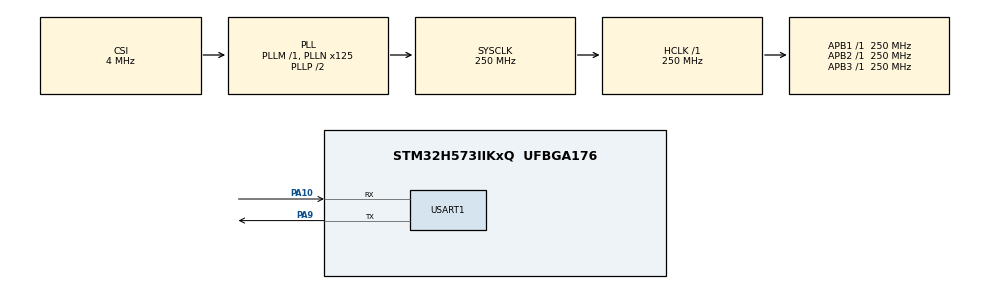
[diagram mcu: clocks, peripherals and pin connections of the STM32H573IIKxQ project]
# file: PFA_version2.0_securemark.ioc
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BOOTPATH.BootPathName=LEGACY
BOOTPATH.UserSelectedBootPath=LEGACY
CORTEX_M33_NS.userName=CORTEX_M33
HASH.Algorithm=HASH_ALGOSELECTION_SHA256
HASH.pKey=__NULL
Mcu.Family=STM32H5
Mcu.Name=STM32H573IIKxQ
Mcu.Package=UFBGA176
NVIC.PriorityGroup=NVIC_PRIORITYGROUP_4
PA10.Mode=Asynchronous
PA10.Signal=USART1_RX
PA9.Mode=Asynchronous
PA9.Signal=USART1_TX
PH0-OSC_IN(PH0).Mode=HSE-DIG-External-Clock-Source
PH0-OSC_IN(PH0).Signal=RCC_OSC_IN
ProjectManager.HeapSize=0x200
ProjectManager.StackSize=0x400
ProjectManager.TargetToolchain=STM32CubeIDE
RCC.ADCFreq_Value=250000000
RCC.AHBFreq_Value=250000000
RCC.APB1Freq_Value=250000000
RCC.APB1TimFreq_Value=250000000
RCC.APB2Freq_Value=250000000
RCC.APB2TimFreq_Value=250000000
RCC.APB3Freq_Value=250000000
RCC.CSI_VALUE=4000000
RCC.CortexFreq_Value=250000000
RCC.EPOD_VALUE=4000000
RCC.HCLKFreq_Value=250000000
RCC.HSE_VALUE=25000000
RCC.HSI48_VALUE=48000000
RCC.HSI_VALUE=64000000
RCC.LSE_VALUE=32768
RCC.LSIRC_VALUE=32000
RCC.PLLFRACN=0
RCC.PLLN=125
RCC.SYSCLKFreq_VALUE=250000000
RCC.SYSCLKSource=RCC_SYSCLKSOURCE_PLLCLK
RCC.USBFreq_Value=48000000
RCC.VCOOutputFreq_Value=500000000
USART1.VirtualMode-Asynchronous=VM_ASYNC
VP_AES_VS_AES.Mode=AES_Activate
VP_BOOTPATH_VS_BOOTPATH.Mode=BP_Activate
VP_CORTEX_M33_NS_VS_Hclk.Mode=Hclk_Mode
VP_HASH_VS_HASH.Mode=HASH_Activate
VP_ICACHE_VS_ICACHE.Mode=DefaultMode
VP_MEMORYMAP_VS_MEMORYMAP.Mode=CurAppReg
VP_PKA_VS_PKA.Mode=PKA_Activate
VP_PWR_VS_LPOM.Mode=PowerOptimisation
VP_PWR_VS_SECSignals.Mode=Security/Privilege
VP_RNG_VS_RNG.Mode=RNG_Activate
board=custom

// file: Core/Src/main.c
/* USER CODE BEGIN Header */
/**
  ******************************************************************************
  * @file           : main.c
  * @brief          : Main program body
  ******************************************************************************
  * @attention
  *
  * Copyright (c) 2025 STMicroelectronics.
  * All rights reserved.
  *
  * This software is licensed under terms that can be found in the LICENSE file
  * in the root directory of this software component.
  * If no LICENSE file comes with this software, it is provided AS-IS.
  *
  ******************************************************************************
  */
/* USER CODE END Header */
#include "main.h"
#include "aes.h"
#include "hash.h"
#include "icache.h"
#include "memorymap.h"
#include "pka.h"
#include "rng.h"
#include "usart.h"
#include "gpio.h"

/* USER CODE BEGIN Includes */
#include "mbedtls_config.h"
//#include "ee_aes.h"
#include "th_lib.h"
#include <stdio.h>
#include <string.h>
#include <stdlib.h>
#include "aes_alt.h"
#include "mbedtls/aes.h"
#include "mbedtls/sha256.h"
#include "sha256_alt.h"

#include "hash.h"
/*
#include "mbedtls/platform_util.h"
#include "mbedtls/platform.h"
#include "hash_stm32.h"
*/
/* USER CODE END Includes */

/* USER CODE BEGIN PV */

mbedtls_aes_context aes_ctx;
mbedtls_sha256_context sha_ctx ;

uint8_t key[16] = {
    0x01, 0x02, 0x03, 0x04,
    0x05, 0x06, 0x07, 0x08,
    0x09, 0x0A, 0x0B, 0x0C,
    0x0D, 0x0E, 0x0F, 0x10
};

uint8_t iv[16] = {
    0x11, 0x12, 0x13, 0x14,
    0x15, 0x16, 0x17, 0x18,
    0x19, 0x1A, 0x1B, 0x1C,
    0x1D, 0x1E, 0x1F, 0x20
};

uint8_t message_buffer[32];
uint8_t message_list[64]="hello from STM32 SecureMark";

/* USER CODE END PV */

void SystemClock_Config(void);
/* USER CODE BEGIN PFP */
#define PUTCHAR_PROTOTYPE int __io_putchar(int ch)
/* USER CODE END PFP */

/* USER CODE BEGIN 0 */
/*int _write(int file, char *ptr, int len){

	HAL_UART_Transmit(&huart1, (uint8_t *)ptr, len, 1000);
	  return len;
}*/
/* USER CODE END 0 */

int main(void)
{

  /* USER CODE BEGIN 1 */
//	 uint32_t aes_time_sw=0;
	 uint32_t aes_time_hw=0;
	 uint32_t sha_time_hw=0;
	  uint32_t t0=0;
	  uint32_t t1=0;

  /* USER CODE END 1 */

  /* MCU Configuration--------------------------------------------------------*/

  /* Reset of all peripherals, Initializes the Flash interface and the Systick. */
  HAL_Init();

  /* Configure the system clock */
  SystemClock_Config();

  /* USER CODE BEGIN SysInit */
  th_timestamp_initialize();
  /* USER CODE END SysInit */

  /* Initialize all configured peripherals */
  MX_GPIO_Init();
  MX_ICACHE_Init();
  MX_AES_Init();
  MX_HASH_Init();
  MX_RNG_Init();
  MX_PKA_Init();
  MX_USART1_UART_Init();
  /* USER CODE BEGIN 2 */
 //AES TEST
  t0= th_timestamp();

  mbedtls_aes_init(&aes_ctx);
  mbedtls_aes_setkey_enc(&aes_ctx, key, 128);
  mbedtls_aes_crypt_ecb(&aes_ctx, MBEDTLS_AES_ENCRYPT,message_buffer, message_list);

  t1= th_timestamp();
   aes_time_hw=t1-t0 ;

    printf("AES encryption Hw took %lu microseconds\r\n", aes_time_hw);

    mbedtls_aes_free(&aes_ctx);

    //SHA_256 TEST
    t0= th_timestamp();

    mbedtls_sha256_init(&sha_ctx);
  uint32_t rets=  mbedtls_sha256_starts_ret(&sha_ctx, 0);
  uint32_t retu=  mbedtls_sha256_update_ret(&sha_ctx,  message_list, strlen((char *)message_list));
  uint32_t retf=  mbedtls_sha256_finish_ret(&sha_ctx, message_buffer);

    t1= th_timestamp();
    sha_time_hw=t1-t0 ;

    printf("SHA_256 Hash Hw took %lu microseconds\r\n", sha_time_hw);
    mbedtls_sha256_free(&sha_ctx);
  /* USER CODE END 2 */

  /* Infinite loop */
   while (1)
  {

  }
}

void SystemClock_Config(void)
{
  RCC_OscInitTypeDef RCC_OscInitStruct = {0};
  RCC_ClkInitTypeDef RCC_ClkInitStruct = {0};

  /** Configure the main internal regulator output voltage
  */
  __HAL_PWR_VOLTAGESCALING_CONFIG(PWR_REGULATOR_VOLTAGE_SCALE0);

  while(!__HAL_PWR_GET_FLAG(PWR_FLAG_VOSRDY)) {}

  /** Initializes the RCC Oscillators according to the specified parameters
  * in the RCC_OscInitTypeDef structure.
  */
  RCC_OscInitStruct.OscillatorType = RCC_OSCILLATORTYPE_HSI48|RCC_OSCILLATORTYPE_CSI;
  RCC_OscInitStruct.HSI48State = RCC_HSI48_ON;
  RCC_OscInitStruct.CSIState = RCC_CSI_ON;
  RCC_OscInitStruct.CSICalibrationValue = RCC_CSICALIBRATION_DEFAULT;
  RCC_OscInitStruct.PLL.PLLState = RCC_PLL_ON;
  RCC_OscInitStruct.PLL.PLLSource = RCC_PLL1_SOURCE_CSI;
  RCC_OscInitStruct.PLL.PLLM = 1;
  RCC_OscInitStruct.PLL.PLLN = 125;
  RCC_OscInitStruct.PLL.PLLP = 2;
  RCC_OscInitStruct.PLL.PLLQ = 2;
  RCC_OscInitStruct.PLL.PLLR = 2;
  RCC_OscInitStruct.PLL.PLLRGE = RCC_PLL1_VCIRANGE_2;
  RCC_OscInitStruct.PLL.PLLVCOSEL = RCC_PLL1_VCORANGE_WIDE;
  RCC_OscInitStruct.PLL.PLLFRACN = 0;
  if (HAL_RCC_OscConfig(&RCC_OscInitStruct) != HAL_OK)
  {
    Error_Handler();
  }

  /** Initializes the CPU, AHB and APB buses clocks
  */
  RCC_ClkInitStruct.ClockType = RCC_CLOCKTYPE_HCLK|RCC_CLOCKTYPE_SYSCLK
                              |RCC_CLOCKTYPE_PCLK1|RCC_CLOCKTYPE_PCLK2
                              |RCC_CLOCKTYPE_PCLK3;
  RCC_ClkInitStruct.SYSCLKSource = RCC_SYSCLKSOURCE_PLLCLK;
  RCC_ClkInitStruct.AHBCLKDivider = RCC_SYSCLK_DIV1;
  RCC_ClkInitStruct.APB1CLKDivider = RCC_HCLK_DIV1;
  RCC_ClkInitStruct.APB2CLKDivider = RCC_HCLK_DIV1;
  RCC_ClkInitStruct.APB3CLKDivider = RCC_HCLK_DIV1;

  if (HAL_RCC_ClockConfig(&RCC_ClkInitStruct, FLASH_LATENCY_5) != HAL_OK)
  {
    Error_Handler();
  }

  /** Configure the programming delay
  */
  __HAL_FLASH_SET_PROGRAM_DELAY(FLASH_PROGRAMMING_DELAY_2);
}

/* USER CODE BEGIN 4 */
PUTCHAR_PROTOTYPE{
 /* Place your implementation of fputc here */
 /* e.g. write a character to USART3 and Loop until the end of transmission */
 HAL_UART_Transmit(&huart1, (uint8_t *)&ch, 1, 0xFFFF);

 return ch;
}
/* USER CODE END 4 */

void Error_Handler(void)
{
  __disable_irq();
  while (1)
  {
  }
}
